# STM32F7x5 register map
File version: 1.4
CPU: CM7 r0p0, little endian, no MPU, no FPU, 3 interrupt priority bits
Registers are 32-bit, read-write, reset 0x0 unless marked. A register's access mark holds for its fields unless they carry their own. Offsets are from the block's base; [hi:lo] are bit positions; {n}, {i} and the like mark numbered series.

## DBG — Debug support
Base 0xE0042000
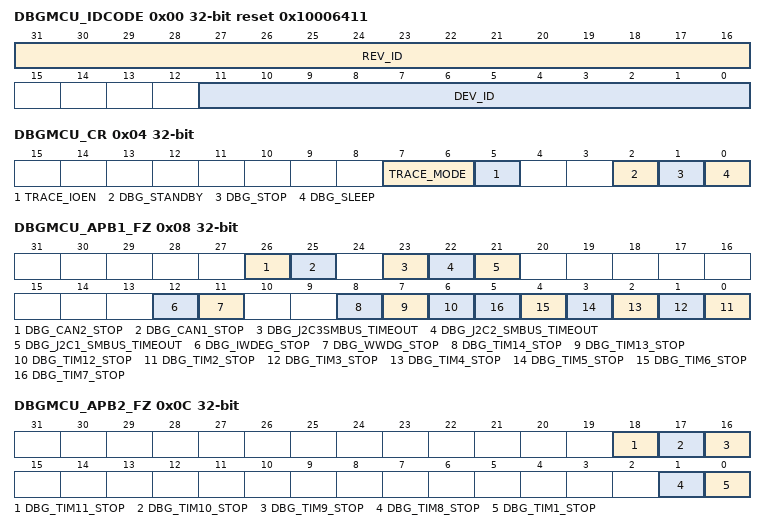
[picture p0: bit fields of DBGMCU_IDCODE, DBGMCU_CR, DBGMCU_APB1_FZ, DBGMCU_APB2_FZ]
0x00 DBGMCU_IDCODE ro reset 0x10006411 — IDCODE
  [31:16] REV_ID, [11:0] DEV_ID
0x04 DBGMCU_CR — Control Register
  [7:6] TRACE_MODE, [5] TRACE_IOEN, [2] DBG_STANDBY, [1] DBG_STOP, [0] DBG_SLEEP
0x08 DBGMCU_APB1_FZ — Debug MCU APB1 Freeze registe
  [26] DBG_CAN2_STOP, [25] DBG_CAN1_STOP, [23] DBG_J2C3SMBUS_TIMEOUT, [22] DBG_J2C2_SMBUS_TIMEOUT, [21] DBG_J2C1_SMBUS_TIMEOUT, [12] DBG_IWDEG_STOP, [11] DBG_WWDG_STOP, [8] DBG_TIM14_STOP, [7] DBG_TIM13_STOP, [6] DBG_TIM12_STOP, [n-2] DBG_TIM{n}_STOP (n=2..7)
0x0C DBGMCU_APB2_FZ — Debug MCU APB2 Freeze registe
  [18] DBG_TIM11_STOP — TIM11 counter stopped when core is halted
  [17] DBG_TIM10_STOP — TIM10 counter stopped when core is halted
  [16] DBG_TIM9_STOP — TIM9 counter stopped when core is halted
  [1] DBG_TIM8_STOP — TIM8 counter stopped when core is halted
  [0] DBG_TIM1_STOP — TIM1 counter stopped when core is halted

## GPIOD — General-purpose I/Os
Base 0x40020C00
Same registers: GPIOC 0x40020800, GPIOE 0x40021000, GPIOF 0x40021400, GPIOG 0x40021800, GPIOH 0x40021C00, GPIOI 0x40022000, GPIOJ 0x40022400, GPIOK 0x40022800
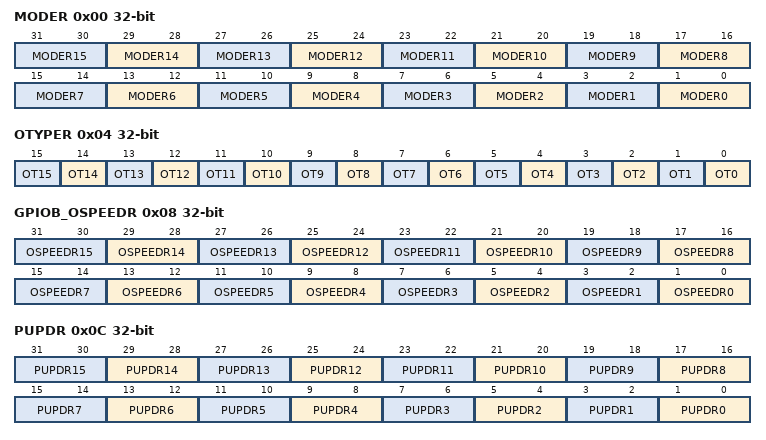
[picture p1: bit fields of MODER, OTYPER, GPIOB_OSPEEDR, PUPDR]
0x00 MODER — GPIO port mode register
  [2n+1:2n] MODER{n} (n=0..15) — Port x configuration bits (y = 0..15)
0x04 OTYPER — GPIO port output type register
  [n] OT{n} (n=0..15) — Port x configuration bits (y = 0..15)
0x08 GPIOB_OSPEEDR — GPIO port output speed register
  [2n+1:2n] OSPEEDR{n} (n=0..15) — Port x configuration bits (y = 0..15)
0x0C PUPDR — GPIO port pull-up/pull-down register
  [2n+1:2n] PUPDR{n} (n=0..15) — Port x configuration bits (y = 0..15)
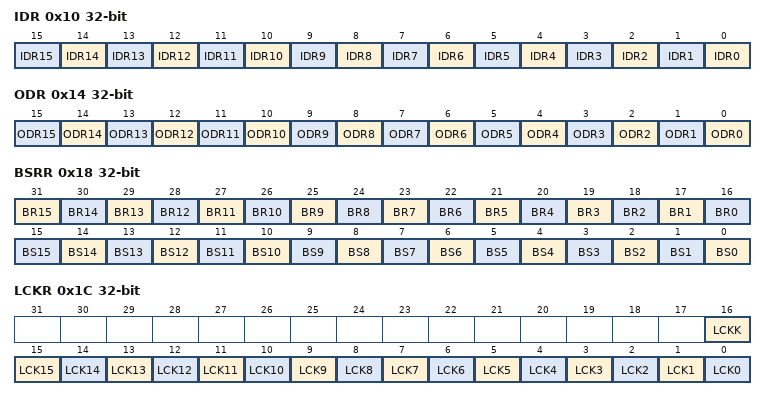
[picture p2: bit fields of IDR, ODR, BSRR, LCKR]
0x10 IDR ro — GPIO port input data register
  [n] IDR{n} (n=0..15) — Port input data (y = 0..15)
0x14 ODR — GPIO port output data register
  [n] ODR{n} (n=0..15) — Port output data (y = 0..15)
0x18 BSRR wo — GPIO port bit set/reset register
  [n+16] BR{n} (n=1..15) — Port x reset bit y (y = 0..15)
  [16] BR0 — Port x set bit y (y= 0..15)
  [n] BS{n} (n=0..15) — Port x set bit y (y= 0..15)
0x1C LCKR — GPIO port configuration lock register
  [16] LCKK — Port x lock bit y (y= 0..15)
  [n] LCK{n} (n=0..15) — Port x lock bit y (y= 0..15)
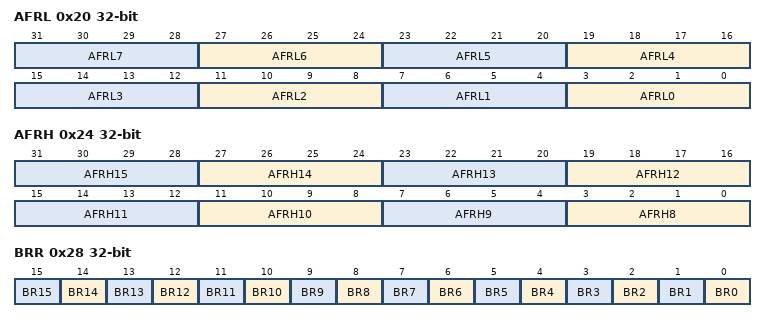
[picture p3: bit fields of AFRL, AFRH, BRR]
0x20 AFRL — GPIO alternate function lowregister
  [4n+3:4n] AFRL{n} (n=0..7) — Alternate function selection for port x bit y (y = 0..7)
0x24 AFRH — GPIO alternate function high register
  [4n-29:4n-32] AFRH{n} (n=8..15) — Alternate function selection for port x bit y (y = 8..15)
0x28 BRR — GPIO port bit reset register
  [n] BR{n} (n=0..15) — Port D Reset bit {n}

## GPIOB — General-purpose I/Os
Base 0x40020400
Registers as GPIOD, without GPIOB_OSPEEDR; these are added or differ:
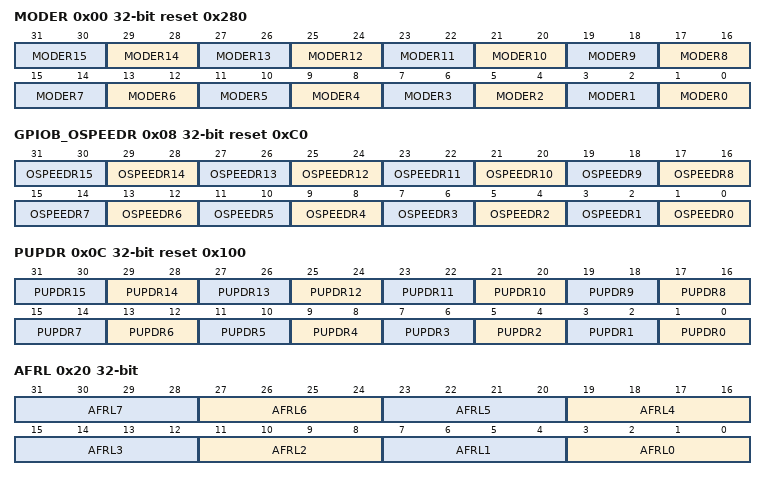
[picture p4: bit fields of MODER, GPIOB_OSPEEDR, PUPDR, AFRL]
0x00 MODER reset 0x280 — GPIO port mode register
  [2n+1:2n] MODER{n} (n=0..15) — Port x configuration bits (y = 0..15)
0x08 GPIOB_OSPEEDR reset 0xC0 — GPIO port output speed register
  [2n+1:2n] OSPEEDR{n} (n=0..15) — Port x configuration bits (y = 0..15)
0x0C PUPDR reset 0x100 — GPIO port pull-up/pull-down register
  [2n+1:2n] PUPDR{n} (n=0..15) — Port x configuration bits (y = 0..15)
0x20 AFRL — GPIO alternate function low register
  [4n+3:4n] AFRL{n} (n=0..7) — Alternate function selection for port x bit y (y = 0..7)
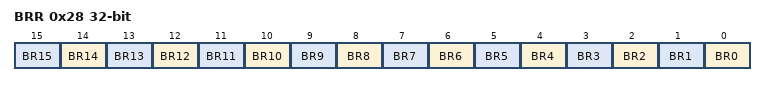
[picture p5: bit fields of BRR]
0x28 BRR — GPIO port bit reset register
  [n] BR{n} (n=0..15) — Port B Reset bit {n}

## GPIOA — General-purpose I/Os
Base 0x40020000
Registers as GPIOB, without GPIOB_OSPEEDR; these are added or differ:
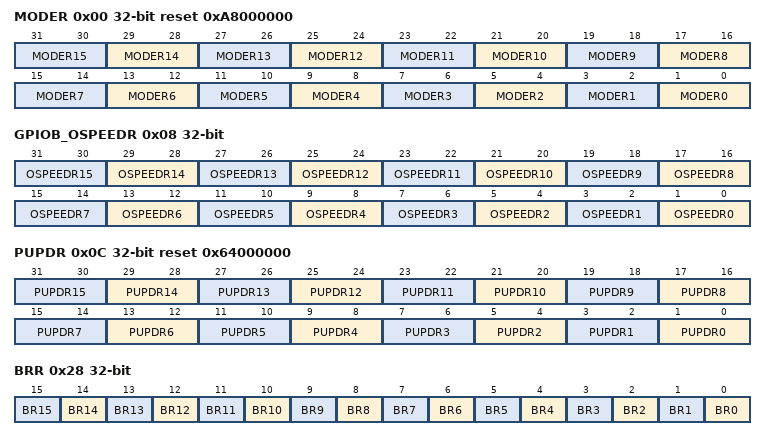
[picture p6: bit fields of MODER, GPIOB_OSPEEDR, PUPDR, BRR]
0x00 MODER reset 0xA8000000 — GPIO port mode register
  [2n+1:2n] MODER{n} (n=0..15) — Port x configuration bits (y = 0..15)
0x08 GPIOB_OSPEEDR — GPIO port output speed register
  [2n+1:2n] OSPEEDR{n} (n=0..15) — Port x configuration bits (y = 0..15)
0x0C PUPDR reset 0x64000000 — GPIO port pull-up/pull-down register
  [2n+1:2n] PUPDR{n} (n=0..15) — Port x configuration bits (y = 0..15)
0x28 BRR — GPIO port bit reset register
  [n] BR{n} (n=0..15) — Port A Reset bit {n}
